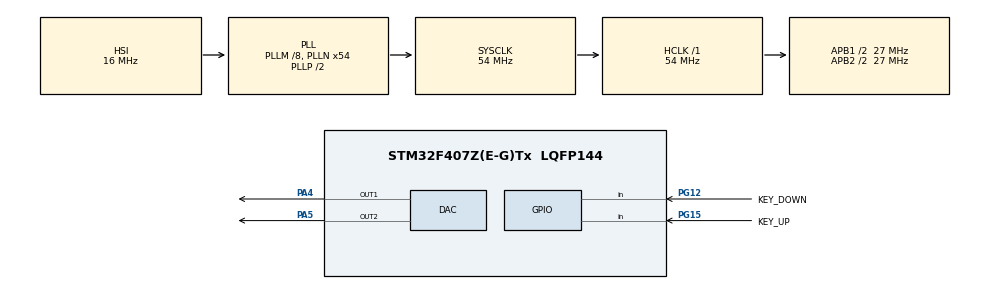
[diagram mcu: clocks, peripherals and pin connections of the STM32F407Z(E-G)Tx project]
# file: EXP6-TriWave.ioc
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DAC.DAC_Trigger=DAC_TRIGGER_NONE
DAC.DAC_Trigger2=DAC_TRIGGER_T2_TRGO
DAC.TriangleAmplitude2=DAC_TRIANGLEAMPLITUDE_4095
DAC.WaveGeneration2=TriangleWaveGeneration
Mcu.Family=STM32F4
Mcu.Name=STM32F407Z(E-G)Tx
Mcu.Package=LQFP144
NVIC.PriorityGroup=NVIC_PRIORITYGROUP_4
PA4.Signal=COMP_DAC1_group
PA5.Signal=COMP_DAC2_group
PG12.GPIO_Label=KEY_DOWN
PG12.Signal=GPIO_Input
PG15.GPIO_Label=KEY_UP
PG15.Signal=GPIO_Input
ProjectManager.HeapSize=0x200
ProjectManager.StackSize=0x400
ProjectManager.TargetToolchain=MDK-ARM V5
RCC.48MHZClocksFreq_Value=27000000
RCC.AHBFreq_Value=54000000
RCC.APB1CLKDivider=RCC_HCLK_DIV2
RCC.APB1Freq_Value=27000000
RCC.APB1TimFreq_Value=54000000
RCC.APB2CLKDivider=RCC_HCLK_DIV2
RCC.APB2Freq_Value=27000000
RCC.APB2TimFreq_Value=54000000
RCC.CortexFreq_Value=54000000
RCC.HCLKFreq_Value=54000000
RCC.HSE_VALUE=25000000
RCC.HSI_VALUE=16000000
RCC.LSE_VALUE=32768
RCC.PLLM=8
RCC.PLLN=54
RCC.SYSCLKFreq_VALUE=54000000
RCC.SYSCLKSource=RCC_SYSCLKSOURCE_PLLCLK
RCC.VCOOutputFreq_Value=108000000
SH.COMP_DAC1_group.0=DAC_OUT1,DAC_OUT1
SH.COMP_DAC2_group.0=DAC_OUT2,DAC_OUT2
TIM2.Period=0xA
TIM2.Prescaler=0x2
TIM2.TIM_MasterOutputTrigger=TIM_TRGO_UPDATE
VP_TIM2_VS_ClockSourceINT.Mode=Internal
board=custom

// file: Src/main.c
/* USER CODE BEGIN Header */
/**
  ******************************************************************************
  * @file           : main.c
  * @brief          : Main program body
  ******************************************************************************
  * @attention
  *
  * <h2><center>&copy; Copyright (c) 2022 STMicroelectronics.
  * All rights reserved.</center></h2>
  *
  * This software component is licensed by ST under BSD 3-Clause license,
  * the "License"; You may not use this file except in compliance with the
  * License. You may obtain a copy of the License at:
  *                        opensource.org/licenses/BSD-3-Clause
  *
  ******************************************************************************
  */
/* USER CODE END Header */

#include "main.h"

DAC_HandleTypeDef hdac;

TIM_HandleTypeDef htim2;

void SystemClock_Config(void);
static void MX_GPIO_Init(void);
static void MX_DAC_Init(void);
static void MX_TIM2_Init(void);

int main(void)
{

  /* MCU Configuration--------------------------------------------------------*/

  /* Reset of all peripherals, Initializes the Flash interface and the Systick. */
  HAL_Init();

  /* Configure the system clock */
  SystemClock_Config();

  /* Initialize all configured peripherals */
  MX_GPIO_Init();
  MX_DAC_Init();
  MX_TIM2_Init();
  /* USER CODE BEGIN 2 */
	HAL_TIM_Base_Start(&htim2);
//	HAL_DAC_Start(&hdac, DAC_CHANNEL_2);
	HAL_DAC_Start(&hdac, DAC_CHANNEL_1);
  /* USER CODE END 2 */

  /* Infinite loop */
  /* USER CODE BEGIN WHILE */
	uint32_t val = 2048-1;
	//HAL_DAC_SetValue(&hdac, DAC_CHANNEL_1, DAC_ALIGN_12B_R, val);
  while (1)
  {
    /* USER CODE END WHILE */
		if(HAL_GPIO_ReadPin(KEY_UP_GPIO_Port,KEY_UP_Pin)==GPIO_PIN_RESET){
			HAL_Delay(10);
			if(HAL_GPIO_ReadPin(KEY_UP_GPIO_Port,KEY_UP_Pin)==GPIO_PIN_RESET){
				if(val+64<4095) val += 64;
				else val = 4095;
				HAL_DAC_SetValue(&hdac, DAC_CHANNEL_1, DAC_ALIGN_12B_R, val);
				HAL_DAC_Start(&hdac, DAC_CHANNEL_1);
			}
		}

		else if(HAL_GPIO_ReadPin(KEY_DOWN_GPIO_Port,KEY_DOWN_Pin)==GPIO_PIN_RESET){
			HAL_Delay(10);
			if(HAL_GPIO_ReadPin(KEY_DOWN_GPIO_Port,KEY_DOWN_Pin)==GPIO_PIN_RESET){
				if(val>64) val -= 64;
				else val = 0;
				HAL_DAC_SetValue(&hdac, DAC_CHANNEL_1, DAC_ALIGN_12B_R, val);
				HAL_DAC_Start(&hdac, DAC_CHANNEL_1);
			}
		}
  }
}

void SystemClock_Config(void)
{
  RCC_OscInitTypeDef RCC_OscInitStruct = {0};
  RCC_ClkInitTypeDef RCC_ClkInitStruct = {0};

  /** Configure the main internal regulator output voltage
  */
  __HAL_RCC_PWR_CLK_ENABLE();
  __HAL_PWR_VOLTAGESCALING_CONFIG(PWR_REGULATOR_VOLTAGE_SCALE1);
  /** Initializes the CPU, AHB and APB busses clocks
  */
  RCC_OscInitStruct.OscillatorType = RCC_OSCILLATORTYPE_HSI;
  RCC_OscInitStruct.HSIState = RCC_HSI_ON;
  RCC_OscInitStruct.HSICalibrationValue = RCC_HSICALIBRATION_DEFAULT;
  RCC_OscInitStruct.PLL.PLLState = RCC_PLL_ON;
  RCC_OscInitStruct.PLL.PLLSource = RCC_PLLSOURCE_HSI;
  RCC_OscInitStruct.PLL.PLLM = 8;
  RCC_OscInitStruct.PLL.PLLN = 54;
  RCC_OscInitStruct.PLL.PLLP = RCC_PLLP_DIV2;
  RCC_OscInitStruct.PLL.PLLQ = 4;
  if (HAL_RCC_OscConfig(&RCC_OscInitStruct) != HAL_OK)
  {
    Error_Handler();
  }
  /** Initializes the CPU, AHB and APB busses clocks
  */
  RCC_ClkInitStruct.ClockType = RCC_CLOCKTYPE_HCLK|RCC_CLOCKTYPE_SYSCLK
                              |RCC_CLOCKTYPE_PCLK1|RCC_CLOCKTYPE_PCLK2;
  RCC_ClkInitStruct.SYSCLKSource = RCC_SYSCLKSOURCE_PLLCLK;
  RCC_ClkInitStruct.AHBCLKDivider = RCC_SYSCLK_DIV1;
  RCC_ClkInitStruct.APB1CLKDivider = RCC_HCLK_DIV2;
  RCC_ClkInitStruct.APB2CLKDivider = RCC_HCLK_DIV2;

  if (HAL_RCC_ClockConfig(&RCC_ClkInitStruct, FLASH_LATENCY_1) != HAL_OK)
  {
    Error_Handler();
  }
}

static void MX_DAC_Init(void)
{

  DAC_ChannelConfTypeDef sConfig = {0};

  /** DAC Initialization
  */
  hdac.Instance = DAC;
  if (HAL_DAC_Init(&hdac) != HAL_OK)
  {
    Error_Handler();
  }
  /** DAC channel OUT2 config
  */
  sConfig.DAC_Trigger = DAC_TRIGGER_T2_TRGO;
  sConfig.DAC_OutputBuffer = DAC_OUTPUTBUFFER_ENABLE;
  if (HAL_DAC_ConfigChannel(&hdac, &sConfig, DAC_CHANNEL_2) != HAL_OK)
  {
    Error_Handler();
  }
  /** Configure Triangle wave generation on DAC OUT2
  */
  if (HAL_DACEx_TriangleWaveGenerate(&hdac, DAC_CHANNEL_2, DAC_TRIANGLEAMPLITUDE_4095) != HAL_OK)
  {
    Error_Handler();
  }

}

static void MX_TIM2_Init(void)
{

  TIM_ClockConfigTypeDef sClockSourceConfig = {0};
  TIM_MasterConfigTypeDef sMasterConfig = {0};

  htim2.Instance = TIM2;
  htim2.Init.Prescaler = 0x2;
  htim2.Init.CounterMode = TIM_COUNTERMODE_UP;
  htim2.Init.Period = 0xA;
  htim2.Init.ClockDivision = TIM_CLOCKDIVISION_DIV1;
  htim2.Init.AutoReloadPreload = TIM_AUTORELOAD_PRELOAD_DISABLE;
  if (HAL_TIM_Base_Init(&htim2) != HAL_OK)
  {
    Error_Handler();
  }
  sClockSourceConfig.ClockSource = TIM_CLOCKSOURCE_INTERNAL;
  if (HAL_TIM_ConfigClockSource(&htim2, &sClockSourceConfig) != HAL_OK)
  {
    Error_Handler();
  }
  sMasterConfig.MasterOutputTrigger = TIM_TRGO_UPDATE;
  sMasterConfig.MasterSlaveMode = TIM_MASTERSLAVEMODE_DISABLE;
  if (HAL_TIMEx_MasterConfigSynchronization(&htim2, &sMasterConfig) != HAL_OK)
  {
    Error_Handler();
  }

}

static void MX_GPIO_Init(void)
{
  GPIO_InitTypeDef GPIO_InitStruct = {0};

  /* GPIO Ports Clock Enable */
  __HAL_RCC_GPIOA_CLK_ENABLE();
  __HAL_RCC_GPIOG_CLK_ENABLE();

  /*Configure GPIO pins : KEY_DOWN_Pin KEY_UP_Pin */
  GPIO_InitStruct.Pin = KEY_DOWN_Pin|KEY_UP_Pin;
  GPIO_InitStruct.Mode = GPIO_MODE_INPUT;
  GPIO_InitStruct.Pull = GPIO_NOPULL;
  HAL_GPIO_Init(GPIOG, &GPIO_InitStruct);

}

void Error_Handler(void)
{
}

/************************ (C) COPYRIGHT STMicroelectronics *****END OF FILE****/
